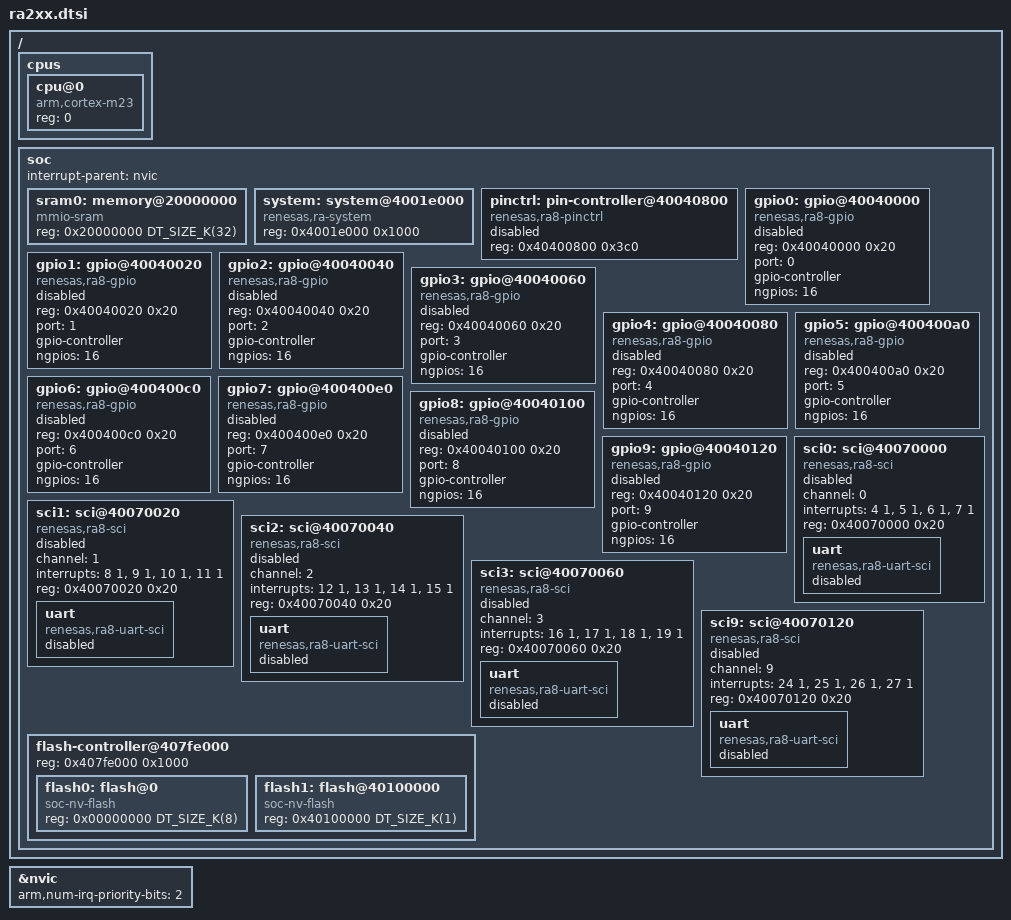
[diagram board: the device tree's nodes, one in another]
/*
 * Copyright (c) 2024 TOKITA Hiroshi
 *
 * SPDX-License-Identifier: Apache-2.0
 */

#include <mem.h>
#include <arm/armv8-m.dtsi>
#include <freq.h>
#include <zephyr/dt-bindings/pinctrl/renesas/ra-pinctrl.h>


/ {
	cpus {
		#address-cells = <1>;
		#size-cells = <0>;

		cpu@0 {
			device_type = "cpu";
			compatible = "arm,cortex-m23";
			reg = <0>;
		};
	};

	soc {
		interrupt-parent = <&nvic>;

		sram0: memory@20000000 {
			compatible = "mmio-sram";
			reg = <0x20000000 DT_SIZE_K(32)>;
		};

		system: system@4001e000 {
			compatible = "renesas,ra-system";
			reg = <0x4001e000 0x1000>;
			status = "okay";
		};

		pinctrl: pin-controller@40040800 {
			compatible = "renesas,ra8-pinctrl";
			reg = <0x40400800 0x3c0>;
			status = "disabled";
		};

		gpio0: gpio@40040000 {
			compatible = "renesas,ra8-gpio";
			reg = <0x40040000 0x20>;
			port = <0>;
			gpio-controller;
			#gpio-cells = <2>;
			ngpios = <16>;
			status = "disabled";
		};

		gpio1: gpio@40040020 {
			compatible = "renesas,ra8-gpio";
			reg = <0x40040020 0x20>;
			port = <1>;
			gpio-controller;
			#gpio-cells = <2>;
			ngpios = <16>;
			status = "disabled";
		};

		gpio2: gpio@40040040 {
			compatible = "renesas,ra8-gpio";
			reg = <0x40040040 0x20>;
			port = <2>;
			gpio-controller;
			#gpio-cells = <2>;
			ngpios = <16>;
			status = "disabled";
		};

		gpio3: gpio@40040060 {
			compatible = "renesas,ra8-gpio";
			reg = <0x40040060 0x20>;
			port = <3>;
			gpio-controller;
			#gpio-cells = <2>;
			ngpios = <16>;
			status = "disabled";
		};

		gpio4: gpio@40040080 {
			compatible = "renesas,ra8-gpio";
			reg = <0x40040080 0x20>;
			port = <4>;
			gpio-controller;
			#gpio-cells = <2>;
			ngpios = <16>;
			status = "disabled";
		};

		gpio5: gpio@400400a0 {
			compatible = "renesas,ra8-gpio";
			reg = <0x400400a0 0x20>;
			port = <5>;
			gpio-controller;
			#gpio-cells = <2>;
			ngpios = <16>;
			status = "disabled";
		};

		gpio6: gpio@400400c0 {
			compatible = "renesas,ra8-gpio";
			reg = <0x400400c0 0x20>;
			port = <6>;
			gpio-controller;
			#gpio-cells = <2>;
			ngpios = <16>;
			status = "disabled";
		};

		gpio7: gpio@400400e0 {
			compatible = "renesas,ra8-gpio";
			reg = <0x400400e0 0x20>;
			port = <7>;
			gpio-controller;
			#gpio-cells = <2>;
			ngpios = <16>;
			status = "disabled";
		};

		gpio8: gpio@40040100 {
			compatible = "renesas,ra8-gpio";
			reg = <0x40040100 0x20>;
			port = <8>;
			gpio-controller;
			#gpio-cells = <2>;
			ngpios = <16>;
			status = "disabled";
		};

		gpio9: gpio@40040120 {
			compatible = "renesas,ra8-gpio";
			reg = <0x40040120 0x20>;
			port = <9>;
			gpio-controller;
			#gpio-cells = <2>;
			ngpios = <16>;
			status = "disabled";
		};

		sci0: sci@40070000 {
			compatible = "renesas,ra8-sci";
			channel = <0>;
			interrupts = <4 1>, <5 1>, <6 1>, <7 1>;
			interrupt-names = "rxi", "txi", "tei", "eri";
			reg = <0x40070000 0x20>;
			status = "disabled";
			uart {
				compatible = "renesas,ra8-uart-sci";
				status = "disabled";
			};
		};

		sci1: sci@40070020 {
			compatible = "renesas,ra8-sci";
			channel = <1>;
			interrupts = <8 1>, <9 1>, <10 1>, <11 1>;
			interrupt-names = "rxi", "txi", "tei", "eri";
			reg = <0x40070020 0x20>;
			status = "disabled";
			uart {
				compatible = "renesas,ra8-uart-sci";
				status = "disabled";
			};
		};

		sci2: sci@40070040 {
			compatible = "renesas,ra8-sci";
			channel = <2>;
			interrupts = <12 1>, <13 1>, <14 1>, <15 1>;
			interrupt-names = "rxi", "txi", "tei", "eri";
			reg = <0x40070040 0x20>;
			status = "disabled";
			uart {
				compatible = "renesas,ra8-uart-sci";
				status = "disabled";
			};
		};

		sci3: sci@40070060 {
			compatible = "renesas,ra8-sci";
			channel = <3>;
			interrupts = <16 1>, <17 1>, <18 1>, <19 1>;
			interrupt-names = "rxi", "txi", "tei", "eri";
			reg = <0x40070060 0x20>;
			status = "disabled";
			uart {
				compatible = "renesas,ra8-uart-sci";
				status = "disabled";
			};
		};

		sci9: sci@40070120 {
			compatible = "renesas,ra8-sci";
			channel = <9>;
			interrupts = <24 1>, <25 1>, <26 1>, <27 1>;
			interrupt-names = "rxi", "txi", "tei", "eri";
			reg = <0x40070120 0x20>;
			status = "disabled";
			uart {
				compatible = "renesas,ra8-uart-sci";
				status = "disabled";
			};
		};

		flash-controller@407fe000 {
			reg = <0x407fe000 0x1000>;
			#address-cells = <1>;
			#size-cells = <1>;

			flash0: flash@0 {
				compatible = "soc-nv-flash";
				reg = <0x00000000 DT_SIZE_K(8)>;
			};
			flash1: flash@40100000 {
				compatible = "soc-nv-flash";
				reg = <0x40100000 DT_SIZE_K(1)>;
			};
		};
	};
};

&nvic {
	arm,num-irq-priority-bits = <2>;
};
